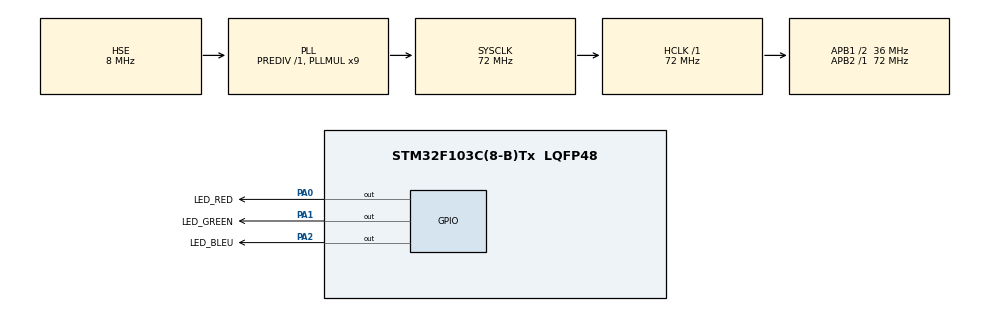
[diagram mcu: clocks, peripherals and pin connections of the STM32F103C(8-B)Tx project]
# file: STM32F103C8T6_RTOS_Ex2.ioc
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FREERTOS.Queues01=myQueue01,16,uint16_t,0,Dynamic,NULL,NULL
FREERTOS.Tasks01=defaultTask,24,128,StartDefaultTask,Default,NULL,Dynamic,NULL,NULL;myTask02,48,128,StartTask02,Default,NULL,Dynamic,NULL,NULL;myTask03,48,128,StartTask03,Default,NULL,Dynamic,NULL,NULL;myTask04,48,128,StartTask04,Default,NULL,Dynamic,NULL,NULL
Mcu.Family=STM32F1
Mcu.Name=STM32F103C(8-B)Tx
Mcu.Package=LQFP48
NVIC.PriorityGroup=NVIC_PRIORITYGROUP_4
NVIC.TIM4_IRQn=true\:15\:0\:false\:false\:true\:false\:false\:true\:true
NVIC.TimeBase=TIM4_IRQn
NVIC.TimeBaseIP=TIM4
PA0-WKUP.GPIO_Label=LED_RED
PA0-WKUP.GPIO_Speed=GPIO_SPEED_FREQ_HIGH
PA0-WKUP.PinState=GPIO_PIN_SET
PA0-WKUP.Signal=GPIO_Output
PA1.GPIO_Label=LED_GREEN
PA1.GPIO_Speed=GPIO_SPEED_FREQ_HIGH
PA1.PinState=GPIO_PIN_SET
PA1.Signal=GPIO_Output
PA13.Mode=Serial_Wire
PA13.Signal=SYS_JTMS-SWDIO
PA14.Mode=Serial_Wire
PA14.Signal=SYS_JTCK-SWCLK
PA2.GPIO_Label=LED_BLEU
PA2.GPIO_Speed=GPIO_SPEED_FREQ_HIGH
PA2.PinState=GPIO_PIN_SET
PA2.Signal=GPIO_Output
PC14-OSC32_IN.Mode=LSE-External-Oscillator
PC14-OSC32_IN.Signal=RCC_OSC32_IN
PC15-OSC32_OUT.Mode=LSE-External-Oscillator
PC15-OSC32_OUT.Signal=RCC_OSC32_OUT
PD0-OSC_IN.Mode=HSE-External-Oscillator
PD0-OSC_IN.Signal=RCC_OSC_IN
PD1-OSC_OUT.Mode=HSE-External-Oscillator
PD1-OSC_OUT.Signal=RCC_OSC_OUT
ProjectManager.HeapSize=0x200
ProjectManager.StackSize=0x400
ProjectManager.TargetToolchain=CMake
RCC.AHBFreq_Value=72000000
RCC.APB1CLKDivider=RCC_HCLK_DIV2
RCC.APB1Freq_Value=36000000
RCC.APB1TimFreq_Value=72000000
RCC.APB2Freq_Value=72000000
RCC.APB2TimFreq_Value=72000000
RCC.EnbaleCSS=true
RCC.HCLKFreq_Value=72000000
RCC.PLLMUL=RCC_PLL_MUL9
RCC.PLLSourceVirtual=RCC_PLLSOURCE_HSE
RCC.SYSCLKFreq_VALUE=72000000
RCC.SYSCLKSource=RCC_SYSCLKSOURCE_PLLCLK
RCC.USBFreq_Value=72000000
VP_FREERTOS_VS_CMSIS_V2.Mode=CMSIS_V2
VP_SYS_VS_tim4.Mode=TIM4
board=custom

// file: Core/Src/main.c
/* USER CODE BEGIN Header */
/**
  ******************************************************************************
  * @file           : main.c
  * @brief          : Main program body
  ******************************************************************************
  * @attention
  *
  * Copyright (c) 2025 STMicroelectronics.
  * All rights reserved.
  *
  * This software is licensed under terms that can be found in the LICENSE file
  * in the root directory of this software component.
  * If no LICENSE file comes with this software, it is provided AS-IS.
  *
  ******************************************************************************
  */
/* USER CODE END Header */
#include "main.h"
#include "cmsis_os.h"

/* Definitions for defaultTask */
osThreadId_t defaultTaskHandle;
const osThreadAttr_t defaultTask_attributes = {
  .name = "defaultTask",
  .stack_size = 128 * 4,
  .priority = (osPriority_t) osPriorityNormal,
};
/* Definitions for myTask02 */
osThreadId_t myTask02Handle;
const osThreadAttr_t myTask02_attributes = {
  .name = "myTask02",
  .stack_size = 128 * 4,
  .priority = (osPriority_t) osPriorityRealtime,
};
/* Definitions for myTask03 */
osThreadId_t myTask03Handle;
const osThreadAttr_t myTask03_attributes = {
  .name = "myTask03",
  .stack_size = 128 * 4,
  .priority = (osPriority_t) osPriorityRealtime,
};
/* Definitions for myTask04 */
osThreadId_t myTask04Handle;
const osThreadAttr_t myTask04_attributes = {
  .name = "myTask04",
  .stack_size = 128 * 4,
  .priority = (osPriority_t) osPriorityRealtime,
};
/* Definitions for myQueue01 */
osMessageQueueId_t myQueue01Handle;
const osMessageQueueAttr_t myQueue01_attributes = {
  .name = "myQueue01"
};

void SystemClock_Config(void);
static void MX_GPIO_Init(void);
void StartDefaultTask(void *argument);
void StartTask02(void *argument);
void StartTask03(void *argument);
void StartTask04(void *argument);

int main(void)
{

  /* MCU Configuration--------------------------------------------------------*/

  /* Reset of all peripherals, Initializes the Flash interface and the Systick. */
  HAL_Init();

  /* Configure the system clock */
  SystemClock_Config();

  /* Initialize all configured peripherals */
  MX_GPIO_Init();

  /* Init scheduler */
  osKernelInitialize();

  /* Create the queue(s) */
  /* creation of myQueue01 */
  myQueue01Handle = osMessageQueueNew (16, sizeof(uint16_t), &myQueue01_attributes);

  /* Create the thread(s) */
  /* creation of defaultTask */
  defaultTaskHandle = osThreadNew(StartDefaultTask, NULL, &defaultTask_attributes);

  /* creation of myTask02 */
  myTask02Handle = osThreadNew(StartTask02, NULL, &myTask02_attributes);

  /* creation of myTask03 */
  myTask03Handle = osThreadNew(StartTask03, NULL, &myTask03_attributes);

  /* creation of myTask04 */
  myTask04Handle = osThreadNew(StartTask04, NULL, &myTask04_attributes);

  /* Start scheduler */
  osKernelStart();

  /* We should never get here as control is now taken by the scheduler */

  /* Infinite loop */
  while (1)
  {

  }
}

void SystemClock_Config(void)
{
  RCC_OscInitTypeDef RCC_OscInitStruct = {0};
  RCC_ClkInitTypeDef RCC_ClkInitStruct = {0};

  /** Initializes the RCC Oscillators according to the specified parameters
  * in the RCC_OscInitTypeDef structure.
  */
  RCC_OscInitStruct.OscillatorType = RCC_OSCILLATORTYPE_HSE;
  RCC_OscInitStruct.HSEState = RCC_HSE_ON;
  RCC_OscInitStruct.HSEPredivValue = RCC_HSE_PREDIV_DIV1;
  RCC_OscInitStruct.HSIState = RCC_HSI_ON;
  RCC_OscInitStruct.PLL.PLLState = RCC_PLL_ON;
  RCC_OscInitStruct.PLL.PLLSource = RCC_PLLSOURCE_HSE;
  RCC_OscInitStruct.PLL.PLLMUL = RCC_PLL_MUL9;
  if (HAL_RCC_OscConfig(&RCC_OscInitStruct) != HAL_OK)
  {
    Error_Handler();
  }

  /** Initializes the CPU, AHB and APB buses clocks
  */
  RCC_ClkInitStruct.ClockType = RCC_CLOCKTYPE_HCLK|RCC_CLOCKTYPE_SYSCLK
                              |RCC_CLOCKTYPE_PCLK1|RCC_CLOCKTYPE_PCLK2;
  RCC_ClkInitStruct.SYSCLKSource = RCC_SYSCLKSOURCE_PLLCLK;
  RCC_ClkInitStruct.AHBCLKDivider = RCC_SYSCLK_DIV1;
  RCC_ClkInitStruct.APB1CLKDivider = RCC_HCLK_DIV2;
  RCC_ClkInitStruct.APB2CLKDivider = RCC_HCLK_DIV1;

  if (HAL_RCC_ClockConfig(&RCC_ClkInitStruct, FLASH_LATENCY_2) != HAL_OK)
  {
    Error_Handler();
  }

  /** Enables the Clock Security System
  */
  HAL_RCC_EnableCSS();
}

static void MX_GPIO_Init(void)
{
  GPIO_InitTypeDef GPIO_InitStruct = {0};

  /* GPIO Ports Clock Enable */
  __HAL_RCC_GPIOC_CLK_ENABLE();
  __HAL_RCC_GPIOD_CLK_ENABLE();
  __HAL_RCC_GPIOA_CLK_ENABLE();

  /*Configure GPIO pin Output Level */
  HAL_GPIO_WritePin(GPIOA, LED_RED_Pin|LED_GREEN_Pin|LED_BLEU_Pin, GPIO_PIN_SET);

  /*Configure GPIO pins : LED_RED_Pin LED_GREEN_Pin LED_BLEU_Pin */
  GPIO_InitStruct.Pin = LED_RED_Pin|LED_GREEN_Pin|LED_BLEU_Pin;
  GPIO_InitStruct.Mode = GPIO_MODE_OUTPUT_PP;
  GPIO_InitStruct.Pull = GPIO_NOPULL;
  GPIO_InitStruct.Speed = GPIO_SPEED_FREQ_HIGH;
  HAL_GPIO_Init(GPIOA, &GPIO_InitStruct);

}

void StartDefaultTask(void *argument)
{
  for(;;)
  {
    osDelay(1);
  }
}

void StartTask02(void *argument)
{
  /* USER CODE BEGIN StartTask02 */
  /* Infinite loop */
  for(;;)
  {
    HAL_GPIO_TogglePin(LED_RED_GPIO_Port, LED_RED_Pin);
    osDelay(10);
  }
  /* USER CODE END StartTask02 */
}

void StartTask03(void *argument)
{
  /* USER CODE BEGIN StartTask03 */
  /* Infinite loop */
  for(;;)
  {
    HAL_GPIO_TogglePin(LED_GREEN_GPIO_Port, LED_GREEN_Pin);
    osDelay(5);
  }
  /* USER CODE END StartTask03 */
}

void StartTask04(void *argument)
{
  /* USER CODE BEGIN StartTask04 */
  /* Infinite loop */
  for(;;)
  {
    HAL_GPIO_TogglePin(LED_BLEU_GPIO_Port, LED_BLEU_Pin);
    osDelay(8);
  }
  /* USER CODE END StartTask04 */
}

void HAL_TIM_PeriodElapsedCallback(TIM_HandleTypeDef *htim)
{
  if (htim->Instance == TIM4)
  {
    HAL_IncTick();
  }
}

void Error_Handler(void)
{
  __disable_irq();
  while (1)
  {
  }
}
